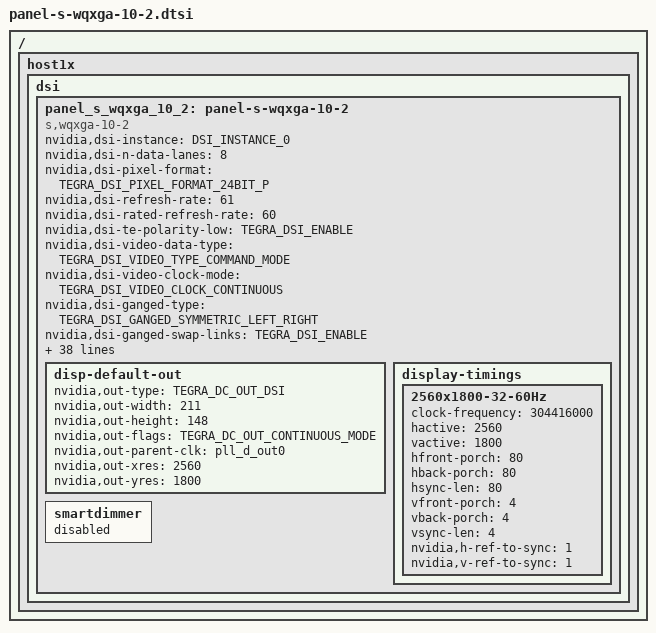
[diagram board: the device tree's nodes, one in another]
/*
 * Copyright (c) 2014-2017, NVIDIA CORPORATION.  All rights reserved.
 *
 * This program is free software; you can redistribute it and/or modify
 * it under the terms of the GNU General Public License as published by
 * the Free Software Foundation; either version 2 of the License, or
 * (at your option) any later version.
 *
 * This program is distributed in the hope that it will be useful, but WITHOUT
 * ANY WARRANTY; without even the implied warranty of MERCHANTABILITY or
 * FITNESS FOR A PARTICULAR PURPOSE.  See the GNU General Public License for
 * more details.
 *
 * You should have received a copy of the GNU General Public License along
 * with this program; if not, see <http://www.gnu.org/licenses/>.
 */

#include <dt-bindings/display/tegra-dc.h>
#include <dt-bindings/display/tegra-panel.h>

/ {
	host1x {
		dsi {
			panel_s_wqxga_10_2: panel-s-wqxga-10-2 {
				status = "okay";
				compatible = "s,wqxga-10-2";
				nvidia,dsi-instance = <DSI_INSTANCE_0>;
				nvidia,dsi-n-data-lanes = <8>;
				nvidia,dsi-pixel-format = <TEGRA_DSI_PIXEL_FORMAT_24BIT_P>;
				nvidia,dsi-refresh-rate = <61>;
				nvidia,dsi-rated-refresh-rate = <60>;
				nvidia,dsi-te-polarity-low = <TEGRA_DSI_ENABLE>;
				nvidia,dsi-video-data-type = <TEGRA_DSI_VIDEO_TYPE_COMMAND_MODE>;
				nvidia,dsi-video-clock-mode = <TEGRA_DSI_VIDEO_CLOCK_CONTINUOUS>;
				nvidia,dsi-ganged-type = <TEGRA_DSI_GANGED_SYMMETRIC_LEFT_RIGHT>;
				nvidia,dsi-ganged-swap-links = <TEGRA_DSI_ENABLE>;
				nvidia,dsi-ganged-write-to-all-links = <TEGRA_DSI_ENABLE>;
				nvidia,dsi-controller-vs = <DSI_VS_1>;
				nvidia,enable-hs-clk-in-lp-mode = <TEGRA_DSI_ENABLE>;
				nvidia,dsi-virtual-channel = <TEGRA_DSI_VIRTUAL_CHANNEL_0>;
				nvidia,dsi-panel-reset = <TEGRA_DSI_ENABLE>;
				nvidia,dsi-power-saving-suspend = <TEGRA_DSI_DISABLE>;
				nvidia,dsi-lp00-pre-panel-wakeup = <TEGRA_DSI_ENABLE>;
				nvidia,dsi-ulpm-not-support = <TEGRA_DSI_ENABLE>;
				nvidia,dsi-bl-name = "backlight";
				nvidia,dsi-init-cmd =
							/* Long  Packet: <PACKETTYPE[u8] COMMANDID[u8] PAYLOADCOUNT[u16] ECC[u8] PAYLOAD[..] CHECKSUM[u16]> */
							/* Short Packet: <PACKETTYPE[u8] COMMANDID[u8] DATA0[u8] DATA1[u8] ECC[u8]> */
							/* For DSI packets each DT cell is interpreted as u8 not u32 */
						//	<TEGRA_DSI_PACKET_CMD DSI_GENERIC_LONG_WRITE 0x3 0x0 0x0 0x10 0x00 0x2A 0x0 0x0>,
							<TEGRA_DSI_PACKET_CMD DSI_DCS_LONG_WRITE 0x5 0x0 0x0 0x2A 0x00 0x00 0x04 0xFF 0x0 0x0>, // COLUMN_ADDRESS= 0x2A,
							<TEGRA_DSI_PACKET_CMD DSI_DCS_LONG_WRITE 0x5 0x0 0x0 0x2B 0x00 0x00 0x07 0x07 0x0 0x0>, // PAGE_ADDRESS= 0x2B,
							<TEGRA_DSI_PACKET_CMD DSI_DCS_WRITE_0_PARAM DSI_DCS_EXIT_SLEEP_MODE 0x0 0x0>,
							<TEGRA_DSI_DELAY_MS 5>,
							<TEGRA_DSI_PACKET_CMD DSI_GENERIC_LONG_WRITE 0x3 0x0 0x0 0x44 0x6 0x6 0x0 0x0>, 
							<TEGRA_DSI_PACKET_CMD DSI_DCS_WRITE_0_PARAM DSI_DCS_SET_TEARING_EFFECT_ON 0x0 0x0>,
							<TEGRA_DSI_PACKET_CMD DSI_DCS_WRITE_1_PARAM 0x36 0x00 0x0>,
							<TEGRA_DSI_PACKET_CMD DSI_DCS_WRITE_1_PARAM 0x3A 0x77 0x0>,
							<TEGRA_DSI_PACKET_CMD DSI_DCS_WRITE_1_PARAM 0x51 0xFF 0x0>,
							<TEGRA_DSI_PACKET_CMD DSI_DCS_WRITE_1_PARAM 0x53 0x24 0x0>,
							<TEGRA_DSI_PACKET_CMD DSI_DCS_WRITE_1_PARAM 0x55 0x00 0x0>,
							<TEGRA_DSI_DELAY_MS 150>,
							<TEGRA_DSI_PACKET_CMD DSI_DCS_WRITE_0_PARAM DSI_DCS_SET_DISPLAY_ON 0x0 0x0>,
							<TEGRA_DSI_SEND_FRAME 6>;
				nvidia,dsi-n-init-cmd = <14>;
				nvidia,dsi-suspend-cmd =
							<TEGRA_DSI_PACKET_CMD DSI_DCS_WRITE_0_PARAM DSI_DCS_SET_DISPLAY_OFF 0x0 0x0>,
							<TEGRA_DSI_DELAY_MS 50>,
							<TEGRA_DSI_PACKET_CMD DSI_DCS_WRITE_0_PARAM DSI_DCS_ENTER_SLEEP_MODE 0x0 0x0>,
							<TEGRA_DSI_DELAY_MS 150>,
							<TEGRA_DSI_PACKET_CMD DSI_DCS_WRITE_0_PARAM DSI_DCS_SET_TEARING_EFFECT_OFF 0x0 0x0>,
							<TEGRA_DSI_DELAY_MS 20>;
				nvidia,dsi-n-suspend-cmd = <6>;
				disp-default-out {
					nvidia,out-type = <TEGRA_DC_OUT_DSI>;
					nvidia,out-width = <211>;
					nvidia,out-height = <148>;
					nvidia,out-flags = <TEGRA_DC_OUT_CONTINUOUS_MODE>;
					nvidia,out-parent-clk = "pll_d_out0";
					nvidia,out-xres = <2560>;
					nvidia,out-yres = <1800>;
				};
				display-timings {
					2560x1800-32-60Hz {
						clock-frequency = <304416000>; //331334 //304416000
						hactive = <2560>;
						vactive = <1800>;
						hfront-porch = <80>;
						hback-porch = <80>;
						hsync-len = <80>;
						vfront-porch = <4>;
						vback-porch = <4>;
						vsync-len = <4>;
						nvidia,h-ref-to-sync = <1>;
						nvidia,v-ref-to-sync = <1>;
					};
				};
				smartdimmer {
					status = "disabled";
				};
			};
		};
	};
};
